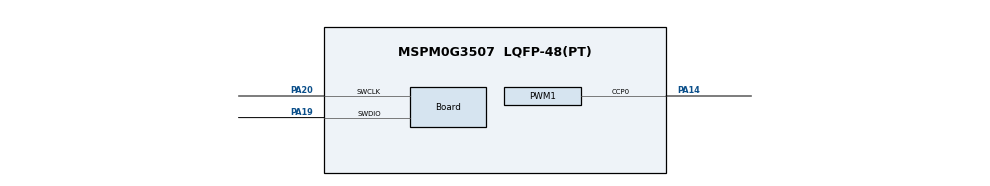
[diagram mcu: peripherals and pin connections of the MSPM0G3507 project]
/**
 * These arguments were used when this file was generated. They will be automatically applied on subsequent loads
 * via the GUI or CLI. Run CLI with '--help' for additional information on how to override these arguments.
 * @cliArgs --device "MSPM0G350X" --part "Default" --package "LQFP-48(PT)" --product "mspm0_sdk@2.04.00.06"
 * @v2CliArgs --device "MSPM0G3507" --package "LQFP-48(PT)" --product "mspm0_sdk@2.04.00.06"
 * @versions {"tool":"1.22.0+3893"}
 */

/**
 * Import the modules used in this configuration.
 */
const Board   = scripting.addModule("/ti/driverlib/Board");
const GPIO    = scripting.addModule("/ti/driverlib/GPIO", {}, false);
const GPIO1   = GPIO.addInstance();
const GPIO2   = GPIO.addInstance();
const GPIO3   = GPIO.addInstance();
const GPIO4   = GPIO.addInstance();
const PWM     = scripting.addModule("/ti/driverlib/PWM", {}, false);
const PWM1    = PWM.addInstance();
const PWM2    = PWM.addInstance();
const SYSCTL  = scripting.addModule("/ti/driverlib/SYSCTL");
const SYSTICK = scripting.addModule("/ti/driverlib/SYSTICK");
const UART    = scripting.addModule("/ti/driverlib/UART", {}, false);
const UART1   = UART.addInstance();

/**
 * Write custom configuration values to the imported modules.
 */
const divider6       = system.clockTree["PLL_CLK2X_DIV"];
divider6.divideValue = 4;

const divider7       = system.clockTree["PLL_PDIV"];
divider7.divideValue = 2;

const divider9       = system.clockTree["UDIV"];
divider9.divideValue = 2;

const multiplier2         = system.clockTree["PLL_QDIV"];
multiplier2.multiplyValue = 10;

const mux8       = system.clockTree["HSCLKMUX"];
mux8.inputSelect = "HSCLKMUX_SYSPLL2X";

Board.InitPriority0               = "/ti/driverlib/MCAN";
Board.peripheral.$assign          = "DEBUGSS";
Board.peripheral.swclkPin.$assign = "PA20";
Board.peripheral.swdioPin.$assign = "PA19";

GPIO1.$name                              = "BSL";
GPIO1.associatedPins[0].$name            = "PIN_18";
GPIO1.associatedPins[0].assignedPin      = "18";
GPIO1.associatedPins[0].assignedPort     = "PORTA";
GPIO1.associatedPins[0].internalResistor = "PULL_DOWN";

GPIO2.$name                              = "I2C";
GPIO2.associatedPins.create(2);
GPIO2.associatedPins[0].$name            = "SDA";
GPIO2.associatedPins[0].assignedPin      = "28";
GPIO2.associatedPins[0].initialValue     = "SET";
GPIO2.associatedPins[1].$name            = "SCL";
GPIO2.associatedPins[1].internalResistor = "PULL_UP";
GPIO2.associatedPins[1].assignedPort     = "PORTA";
GPIO2.associatedPins[1].assignedPin      = "31";
GPIO2.associatedPins[1].initialValue     = "SET";

GPIO3.$name                          = "TB6612";
GPIO3.associatedPins.create(5);
GPIO3.associatedPins[0].$name        = "STBY";
GPIO3.associatedPins[0].initialValue = "SET";
GPIO3.associatedPins[0].assignedPort = "PORTA";
GPIO3.associatedPins[0].assignedPin  = "12";
GPIO3.associatedPins[1].$name        = "AIN1";
GPIO3.associatedPins[1].initialValue = "SET";
GPIO3.associatedPins[1].assignedPort = "PORTB";
GPIO3.associatedPins[1].assignedPin  = "6";
GPIO3.associatedPins[2].$name        = "AIN2";
GPIO3.associatedPins[2].initialValue = "SET";
GPIO3.associatedPins[2].assignedPin  = "7";
GPIO3.associatedPins[2].assignedPort = "PORTB";
GPIO3.associatedPins[3].$name        = "BIN1";
GPIO3.associatedPins[3].initialValue = "SET";
GPIO3.associatedPins[3].assignedPin  = "8";
GPIO3.associatedPins[3].assignedPort = "PORTA";
GPIO3.associatedPins[4].$name        = "BIN2";
GPIO3.associatedPins[4].initialValue = "SET";
GPIO3.associatedPins[4].assignedPin  = "9";
GPIO3.associatedPins[4].assignedPort = "PORTA";

GPIO4.$name                               = "ENCODER";
GPIO4.associatedPins.create(4);
GPIO4.associatedPins[0].$name             = "L_A";
GPIO4.associatedPins[0].direction         = "INPUT";
GPIO4.associatedPins[0].assignedPort      = "PORTB";
GPIO4.associatedPins[0].assignedPin       = "24";
GPIO4.associatedPins[0].internalResistor  = "PULL_UP";
GPIO4.associatedPins[1].$name             = "L_B";
GPIO4.associatedPins[1].direction         = "INPUT";
GPIO4.associatedPins[1].assignedPort      = "PORTB";
GPIO4.associatedPins[1].assignedPin       = "20";
GPIO4.associatedPins[1].interruptEn       = true;
GPIO4.associatedPins[1].polarity          = "RISE_FALL";
GPIO4.associatedPins[1].internalResistor  = "PULL_UP";
GPIO4.associatedPins[1].interruptPriority = "1";
GPIO4.associatedPins[2].$name             = "R_A";
GPIO4.associatedPins[2].direction         = "INPUT";
GPIO4.associatedPins[2].assignedPort      = "PORTA";
GPIO4.associatedPins[2].assignedPin       = "15";
GPIO4.associatedPins[2].internalResistor  = "PULL_UP";
GPIO4.associatedPins[3].$name             = "R_B";
GPIO4.associatedPins[3].direction         = "INPUT";
GPIO4.associatedPins[3].assignedPort      = "PORTA";
GPIO4.associatedPins[3].assignedPin       = "16";
GPIO4.associatedPins[3].polarity          = "RISE_FALL";
GPIO4.associatedPins[3].interruptEn       = true;
GPIO4.associatedPins[3].internalResistor  = "PULL_UP";
GPIO4.associatedPins[3].interruptPriority = "1";

PWM1.$name                              = "PWM_R";
PWM1.timerStartTimer                    = true;
PWM1.clockDivider                       = 8;
PWM1.ccIndex                            = [0];
PWM1.peripheral.ccp0Pin.$assign         = "PA14";
PWM1.PWM_CHANNEL_0.$name                = "ti_driverlib_pwm_PWMTimerCC0";
PWM1.ccp0PinConfig.$name                = "ti_driverlib_gpio_GPIOPinGeneric0";
PWM1.ccp0PinConfig.direction            = scripting.forceWrite("OUTPUT");
PWM1.ccp0PinConfig.hideOutputInversion  = scripting.forceWrite(false);
PWM1.ccp0PinConfig.onlyInternalResistor = scripting.forceWrite(false);
PWM1.ccp0PinConfig.passedPeripheralType = scripting.forceWrite("Digital");

PWM2.$name                              = "PWM_L";
PWM2.clockDivider                       = 8;
PWM2.ccIndex                            = [1];
PWM2.timerStartTimer                    = true;
PWM2.peripheral.$assign                 = "TIMG0";
PWM2.ccp1PinConfig.direction            = scripting.forceWrite("OUTPUT");
PWM2.ccp1PinConfig.hideOutputInversion  = scripting.forceWrite(false);
PWM2.ccp1PinConfig.onlyInternalResistor = scripting.forceWrite(false);
PWM2.ccp1PinConfig.passedPeripheralType = scripting.forceWrite("Digital");
PWM2.ccp1PinConfig.$name                = "ti_driverlib_gpio_GPIOPinGeneric1";
PWM2.PWM_CHANNEL_1.$name                = "ti_driverlib_pwm_PWMTimerCC1";

SYSCTL.forceDefaultClkConfig = true;
SYSCTL.peripheral.$assign    = "SYSCTL";

SYSTICK.periodEnable      = true;
SYSTICK.interruptEnable   = true;
SYSTICK.systickEnable     = true;
SYSTICK.period            = 32000;
SYSTICK.interruptPriority = "0";

UART1.$name                            = "HC_06";
UART1.peripheral.$assign               = "UART2";
UART1.txPinConfig.direction            = scripting.forceWrite("OUTPUT");
UART1.txPinConfig.hideOutputInversion  = scripting.forceWrite(false);
UART1.txPinConfig.onlyInternalResistor = scripting.forceWrite(false);
UART1.txPinConfig.passedPeripheralType = scripting.forceWrite("Digital");
UART1.txPinConfig.$name                = "ti_driverlib_gpio_GPIOPinGeneric2";
UART1.rxPinConfig.hideOutputInversion  = scripting.forceWrite(false);
UART1.rxPinConfig.onlyInternalResistor = scripting.forceWrite(false);
UART1.rxPinConfig.passedPeripheralType = scripting.forceWrite("Digital");
UART1.rxPinConfig.$name                = "ti_driverlib_gpio_GPIOPinGeneric3";

const ProjectConfig              = scripting.addModule("/ti/project_config/ProjectConfig", {}, false);
ProjectConfig.migrationCondition = true;

/**
 * Pinmux solution for unlocked pins/peripherals. This ensures that minor changes to the automatic solver in a future
 * version of the tool will not impact the pinmux you originally saw.  These lines can be completely deleted in order to
 * re-solve from scratch.
 */
GPIO1.associatedPins[0].pin.$suggestSolution = "PA18";
GPIO2.associatedPins[0].pin.$suggestSolution = "PA28";
GPIO2.associatedPins[1].pin.$suggestSolution = "PA31";
GPIO3.associatedPins[0].pin.$suggestSolution = "PA12";
GPIO3.associatedPins[1].pin.$suggestSolution = "PB6";
GPIO3.associatedPins[2].pin.$suggestSolution = "PB7";
GPIO3.associatedPins[3].pin.$suggestSolution = "PA8";
GPIO3.associatedPins[4].pin.$suggestSolution = "PA9";
GPIO4.associatedPins[0].pin.$suggestSolution = "PB24";
GPIO4.associatedPins[1].pin.$suggestSolution = "PB20";
GPIO4.associatedPins[2].pin.$suggestSolution = "PA15";
GPIO4.associatedPins[3].pin.$suggestSolution = "PA16";
PWM1.peripheral.$suggestSolution             = "TIMG12";
PWM2.peripheral.ccp1Pin.$suggestSolution     = "PA13";
UART1.peripheral.rxPin.$suggestSolution      = "PA22";
UART1.peripheral.txPin.$suggestSolution      = "PA21";
